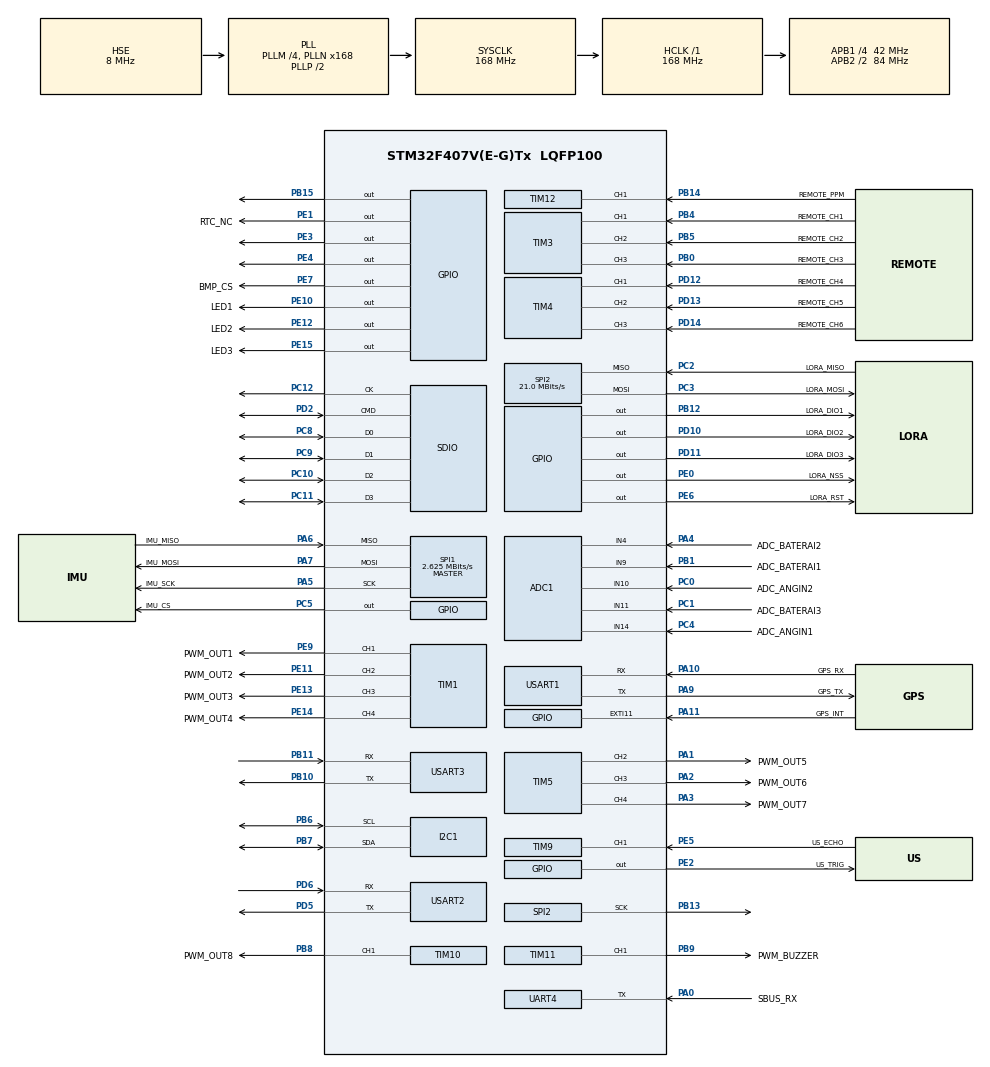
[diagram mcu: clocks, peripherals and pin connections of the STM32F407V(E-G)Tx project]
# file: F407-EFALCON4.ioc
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PD12.GPIO_Label=REMOTE_CH4
PH0-OSC_IN.Signal=RCC_OSC_IN
SH.S_TIM1_CH4.0=TIM1_CH4,PWM Generation4 CH4
TIM4.Channel-Input_Capture3_from_TI3=TIM_CHANNEL_3
SPI1.VirtualType=VM_MASTER
SPI2.VirtualType=VM_MASTER
TIM12.ICPolarity_CH2=TIM_INPUTCHANNELPOLARITY_RISING
PB10.Mode=Asynchronous
TIM12.ICPolarity_CH1=TIM_INPUTCHANNELPOLARITY_FALLING
NVIC.TIM6_DAC_IRQn=true\:5\:0\:false\:true\:true\:3\:true\:true\:true
VP_FATFS_VS_SDIO.Mode=SDIO
PC12.Signal=SDIO_CK
PB14.GPIO_Label=REMOTE_PPM
FREERTOS.Events01=IMUEvent,Dynamic,NULL;RemoteEvent,Dynamic,NULL
PE10.GPIO_PuPd=GPIO_NOPULL
PA6.GPIO_Label=IMU_MISO
PB13.Signal=SPI2_SCK
PE6.GPIO_Label=LORA_RST
RCC.SYSCLKSource=RCC_SYSCLKSOURCE_PLLCLK
FREERTOS.configENABLE_FPU=1
SPI1.Direction=SPI_DIRECTION_2LINES
UART4.Mode=MODE_RX
RCC.APB2TimFreq_Value=168000000
PB6.Signal=I2C1_SCL
VP_TIM10_VS_ClockSourceINT.Mode=Enable_Timer
PB6.Mode=I2C
SPI1.CalculateBaudRate=2.625 MBits/s
PC3.Signal=SPI2_MOSI
PE5.Signal=S_TIM9_CH1
PE1.Signal=GPIO_Output
FREERTOS.configMINIMAL_STACK_SIZE=512
TIM3.Channel-Input_Capture1_from_TI1=TIM_CHANNEL_1
TIM10.Channel=TIM_CHANNEL_1
PB12.GPIO_Label=LORA_DIO1
SH.S_TIM12_CH1.0=TIM12_CH1,Input_Capture1_from_TI1
PC4.GPIO_Label=ADC_ANGIN1
TIM1.Channel-PWM\ Generation1\ CH1=TIM_CHANNEL_1
PE9.Signal=S_TIM1_CH1
SH.S_TIM12_CH1.1=TIM12_CH1,Input_Capture2_from_TI1
PB1.GPIO_Label=ADC_BATERAI1
PC9.Mode=SD_4_bits_Wide_bus
SPI2.CalculateBaudRate=21.0 MBits/s
SH.S_TIM4_CH2.0=TIM4_CH2,Input_Capture2_from_TI2
PE2.Signal=GPIO_Output
TIM12.Channel-Input_Capture2_from_TI1=TIM_CHANNEL_2
PE10.Signal=GPIO_Output
ADC1.SamplingTime-0\#ChannelRegularConversion=ADC_SAMPLETIME_3CYCLES
Mcu.Package=LQFP100
PB9.Signal=S_TIM11_CH1
PB1.Signal=ADCx_IN9
PB14.GPIO_PuPd=GPIO_NOPULL
NVIC.TimeBase=TIM7_IRQn
SPI2.Mode=SPI_MODE_MASTER
SH.ADCx_IN14.0=ADC1_IN14,IN14
PD12.Signal=S_TIM4_CH1
NVIC.TimeBaseIP=TIM7
PA10.Signal=USART1_RX
PE12.GPIO_Label=LED2
PC11.Mode=SD_4_bits_Wide_bus
SH.ADCx_IN9.0=ADC1_IN9,IN9
RCC.APB2CLKDivider=RCC_HCLK_DIV2
SH.S_TIM4_CH1.0=TIM4_CH1,Input_Capture1_from_TI1
RCC.APB1TimFreq_Value=84000000
PB13.Mode=Full_Duplex_Master
PE10.GPIO_Label=LED1
PA4.GPIO_Label=ADC_BATERAI2
PA5.Mode=Full_Duplex_Master
FREERTOS.Tasks01=IMU_Task,48,512,Start_IMU_Task,Default,NULL,Dynamic,NULL,NULL;Remote_Task,27,512,Start_Remote_Task,Default,NULL,Dynamic,NULL,NULL;PrintSerial_Tas,24,512,Start_PrintSerial_Task,Default,NULL,Dynamic,NULL,NULL;BMP_Task,8,512,Start_BMP_Task,Default,NULL,Dynamic,NULL,NULL
ADC1.Rank-0\#ChannelRegularConversion=1
TIM3.Channel-Input_Capture2_from_TI2=TIM_CHANNEL_2
PA9.GPIO_Label=GPS_TX
PC2.Signal=SPI2_MISO
PA11.GPIO_Label=GPS_INT
PE7.PinState=GPIO_PIN_SET
TIM5.Channel-PWM\ Generation3\ CH3=TIM_CHANNEL_3
PC0.Signal=ADCx_IN10
RCC.APB1CLKDivider=RCC_HCLK_DIV4
UART4.VirtualMode=Asynchronous
PD6.Mode=Asynchronous
PA0-WKUP.GPIO_Label=SBUS_RX
PA0-WKUP.Signal=UART4_TX
PA0-WKUP.Mode=Half_duplex(single_wire_mode)
PD10.Signal=GPIO_Output
PB8.GPIO_Label=PWM_OUT8
PB11.Mode=Asynchronous
PA9.Signal=USART1_TX
TIM1.Channel-PWM\ Generation2\ CH2=TIM_CHANNEL_2
SDIO.ClockDiv=4
PE9.GPIO_Label=PWM_OUT1
PB10.Signal=USART3_TX
ARM.CMSIS.5.6.0.CMSISJjCORE=true
TIM12.Prescaler=84 - 1
PB14.Signal=S_TIM12_CH1
PA5.Signal=SPI1_SCK
PC12.Mode=SD_4_bits_Wide_bus
PE1.GPIO_Label=RTC_NC
PE14.Signal=S_TIM1_CH4
PE15.Signal=GPIO_Output
PB4.GPIO_Label=REMOTE_CH1
SPI1.Mode=SPI_MODE_MASTER
SH.S_TIM9_CH1.1=TIM9_CH1,Input_Capture2_from_TI1
PA1.GPIO_Label=PWM_OUT5
SH.S_TIM9_CH1.0=TIM9_CH1,Input_Capture1_from_TI1
SH.ADCx_IN4.0=ADC1_IN4,IN4
PA13.Mode=Serial_Wire
PC8.Mode=SD_4_bits_Wide_bus
TIM5.Channel-PWM\ Generation2\ CH2=TIM_CHANNEL_2
PA4.Signal=ADCx_IN4
TIM12.Channel-Input_Capture1_from_TI1=TIM_CHANNEL_1
PB5.Signal=S_TIM3_CH2
ADC1.master=1
PE13.GPIO_Label=PWM_OUT3
PA5.GPIO_Label=IMU_SCK
PD11.Signal=GPIO_Output
PE5.GPIO_Label=US_ECHO
USART1.VirtualMode=VM_ASYNC
PA11.Signal=GPXTI11
ProjectManager.HeapSize=0x200
NVIC.PriorityGroup=NVIC_PRIORITYGROUP_4
PE3.Signal=GPIO_Output
PC3.GPIO_Label=LORA_MOSI
TIM9.Channel-Input_Capture2_from_TI1=TIM_CHANNEL_2
TIM1.Channel-PWM\ Generation3\ CH3=TIM_CHANNEL_3
PD2.Signal=SDIO_CMD
PB0.Signal=S_TIM3_CH3
PC1.Signal=ADCx_IN11
Mcu.Family=STM32F4
PC3.Mode=Full_Duplex_Master
PA6.Mode=Full_Duplex_Master
RCC.CortexFreq_Value=168000000
PE11.GPIO_Label=PWM_OUT2
PC10.Signal=SDIO_D2
SH.S_TIM5_CH2.0=TIM5_CH2,PWM Generation2 CH2
PC0.GPIO_Label=ADC_ANGIN2
PB0.GPIO_Label=REMOTE_CH3
PB11.Signal=USART3_RX
PB15.Signal=GPIO_Output
ProjectManager.StackSize=0x400
VP_FREERTOS_VS_CMSIS_V2.Mode=CMSIS_V2
TIM4.Channel-Input_Capture1_from_TI1=TIM_CHANNEL_1
PD13.Signal=S_TIM4_CH2
TIM3.Channel-Input_Capture3_from_TI3=TIM_CHANNEL_3
TIM1.Channel-PWM\ Generation4\ CH4=TIM_CHANNEL_4
PD11.GPIO_Label=LORA_DIO3
RCC.HCLKFreq_Value=168000000
SH.S_TIM5_CH3.0=TIM5_CH3,PWM Generation3 CH3
RCC.AHBFreq_Value=168000000
PH0-OSC_IN.Mode=HSE-External-Oscillator
PD5.Mode=Asynchronous
ADC1.Channel-0\#ChannelRegularConversion=ADC_CHANNEL_9
RCC.HSE_VALUE=8000000
PE13.Signal=S_TIM1_CH3
TIM5.Channel-PWM\ Generation4\ CH4=TIM_CHANNEL_4
PA14.Mode=Serial_Wire
PA10.GPIO_Label=GPS_RX
PB7.Signal=I2C1_SDA
SH.S_TIM3_CH1.0=TIM3_CH1,Input_Capture1_from_TI1
TIM6.Period=100 - 1
PE4.Signal=GPIO_Output
PH1-OSC_OUT.Mode=HSE-External-Oscillator
PD13.GPIO_Label=REMOTE_CH5
PA6.Signal=SPI1_MISO
USART2.VirtualMode=VM_ASYNC
SH.S_TIM10_CH1.0=TIM10_CH1,PWM Generation1 CH1
PA2.GPIO_Label=PWM_OUT6
PE0.GPIO_Label=LORA_NSS
PB5.GPIO_Label=REMOTE_CH2
SPI2.Direction=SPI_DIRECTION_2LINES
PC5.Signal=GPIO_Output
PE7.Signal=GPIO_Output
PD6.Signal=USART2_RX
SH.S_TIM11_CH1.0=TIM11_CH1,PWM Generation1 CH1
SPI1.BaudRatePrescaler=SPI_BAUDRATEPRESCALER_32
PE2.GPIO_Label=US_TRIG
PC2.GPIO_Label=LORA_MISO
NVIC.TIM7_IRQn=true\:0\:0\:false\:false\:true\:false\:false\:true
PB4.Signal=S_TIM3_CH1
PA3.Signal=S_TIM5_CH4
PE10.PinState=GPIO_PIN_SET
RCC.PLLSourceVirtual=RCC_PLLSOURCE_HSE
PA7.Mode=Full_Duplex_Master
PB9.GPIO_Label=PWM_BUZZER
PA10.Mode=Asynchronous
PC11.Signal=SDIO_D3
VP_SYS_VS_tim7.Mode=TIM7
PC8.Signal=SDIO_D0
TIM6.Prescaler=84 - 1
PC4.Signal=ADCx_IN14
PC10.Mode=SD_4_bits_Wide_bus
VP_TIM6_VS_ClockSourceINT.Mode=Enable_Timer
ARM.CMSIS.5.6.0.CMSISJjDSP=Library
PC2.Mode=Full_Duplex_Master
PE14.GPIO_Label=PWM_OUT4
PD5.Signal=USART2_TX
PC5.GPIO_PuPd=GPIO_NOPULL
SH.S_TIM3_CH3.0=TIM3_CH3,Input_Capture3_from_TI3
NVIC.USART2_IRQn=true\:5\:0\:false\:false\:true\:true\:true\:true
TIM4.Channel-Input_Capture2_from_TI2=TIM_CHANNEL_2
VP_TIM11_VS_ClockSourceINT.Mode=Enable_Timer
PA13.Signal=SYS_JTMS-SWDIO
PA9.Mode=Asynchronous
SH.S_TIM1_CH1.0=TIM1_CH1,PWM Generation1 CH1
PE15.GPIO_Label=LED3
ProjectManager.TargetToolchain=STM32CubeIDE
NVIC.TIM8_BRK_TIM12_IRQn=true\:5\:0\:false\:true\:true\:2\:true\:true\:true
SH.S_TIM4_CH3.0=TIM4_CH3,Input_Capture3_from_TI3
PD10.GPIO_Label=LORA_DIO2
PE11.Signal=S_TIM1_CH2
RCC.LSE_VALUE=32768
PA1.Signal=S_TIM5_CH2
TIM9.Channel-Input_Capture1_from_TI1=TIM_CHANNEL_1
PD2.Mode=SD_4_bits_Wide_bus
SH.S_TIM3_CH2.0=TIM3_CH2,Input_Capture2_from_TI2
board=custom
RCC.VCOOutputFreq_Value=336000000
VP_ARM.CMSIS_VS_CMSISJjDSP_1.7.0_5.6.0.Mode=CMSISJjDSP
RCC.APB2Freq_Value=84000000
SH.ADCx_IN11.0=ADC1_IN11,IN11
SH.S_TIM1_CH2.0=TIM1_CH2,PWM Generation2 CH2
VP_TIM2_VS_ClockSourceINT.Mode=Internal
PC1.GPIO_Label=ADC_BATERAI3
PH1-OSC_OUT.Signal=RCC_OSC_OUT
SH.S_TIM5_CH4.0=TIM5_CH4,PWM Generation4 CH4
PD14.GPIO_Label=REMOTE_CH6
PE6.Signal=GPIO_Output
Mcu.Name=STM32F407V(E-G)Tx
PE0.Signal=GPIO_Output
PE7.GPIO_Label=BMP_CS
PE12.Signal=GPIO_Output
PA2.Signal=S_TIM5_CH3
PE12.PinState=GPIO_PIN_SET
PD14.Signal=S_TIM4_CH3
RCC.48MHZClocksFreq_Value=48000000
RCC.SYSCLKFreq_VALUE=168000000
PA7.GPIO_Label=IMU_MOSI
PC5.PinState=GPIO_PIN_SET
PC5.GPIO_Label=IMU_CS
USART3.VirtualMode=VM_ASYNC
PB7.Mode=I2C
PA14.Signal=SYS_JTCK-SWCLK
SH.ADCx_IN10.0=ADC1_IN10,IN10
SH.S_TIM1_CH3.0=TIM1_CH3,PWM Generation3 CH3
RCC.HSI_VALUE=16000000
RCC.PLLQ=7
ADC1.NbrOfConversionFlag=1
RCC.PLLM=4
RCC.PLLN=168
TIM11.Channel=TIM_CHANNEL_1
PB8.Signal=S_TIM10_CH1
PC9.Signal=SDIO_D1
RCC.APB1Freq_Value=42000000
PB12.Signal=GPIO_Output
PA3.GPIO_Label=PWM_OUT7
PA7.Signal=SPI1_MOSI

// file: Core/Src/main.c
/* USER CODE BEGIN Header */
/**
  ******************************************************************************
  * @file           : main.c
  * @brief          : Main program body
  ******************************************************************************
  * @attention
  *
  * <h2><center>&copy; Copyright (c) 2021 STMicroelectronics.
  * All rights reserved.</center></h2>
  *
  * This software component is licensed by ST under BSD 3-Clause license,
  * the "License"; You may not use this file except in compliance with the
  * License. You may obtain a copy of the License at:
  *                        opensource.org/licenses/BSD-3-Clause
  *
  ******************************************************************************
  */
/* USER CODE END Header */
#include "main.h"
#include "cmsis_os.h"
#include "fatfs.h"

/* USER CODE BEGIN Includes */
#include <stdio.h>
#include <string.h>
#include <stdbool.h>

#include "MPU9250.h"
#include "IMU.h"
#include "Fusion.h"
#include "bmp2.h"
#include "retarget.h"
#include "bmp2_app.h"
#include "Kalman.h"
/* USER CODE END Includes */

/* USER CODE BEGIN PD */
#define SERIAL_DEBUG huart2
/* USER CODE END PD */

ADC_HandleTypeDef hadc1;

I2C_HandleTypeDef hi2c1;

SD_HandleTypeDef hsd;

SPI_HandleTypeDef hspi1;
SPI_HandleTypeDef hspi2;

TIM_HandleTypeDef htim1;
TIM_HandleTypeDef htim2;
TIM_HandleTypeDef htim3;
TIM_HandleTypeDef htim4;
TIM_HandleTypeDef htim5;
TIM_HandleTypeDef htim6;
TIM_HandleTypeDef htim9;
TIM_HandleTypeDef htim10;
TIM_HandleTypeDef htim11;
TIM_HandleTypeDef htim12;

UART_HandleTypeDef huart4;
UART_HandleTypeDef huart1;
UART_HandleTypeDef huart2;
UART_HandleTypeDef huart3;

/* Definitions for IMU_Task */
osThreadId_t IMU_TaskHandle;
const osThreadAttr_t IMU_Task_attributes = {
  .name = "IMU_Task",
  .stack_size = 512 * 4,
  .priority = (osPriority_t) osPriorityRealtime,
};
/* Definitions for Remote_Task */
osThreadId_t Remote_TaskHandle;
const osThreadAttr_t Remote_Task_attributes = {
  .name = "Remote_Task",
  .stack_size = 512 * 4,
  .priority = (osPriority_t) osPriorityNormal3,
};
/* Definitions for PrintSerial_Tas */
osThreadId_t PrintSerial_TasHandle;
const osThreadAttr_t PrintSerial_Tas_attributes = {
  .name = "PrintSerial_Tas",
  .stack_size = 512 * 4,
  .priority = (osPriority_t) osPriorityNormal,
};
/* Definitions for BMP_Task */
osThreadId_t BMP_TaskHandle;
const osThreadAttr_t BMP_Task_attributes = {
  .name = "BMP_Task",
  .stack_size = 512 * 4,
  .priority = (osPriority_t) osPriorityLow,
};
/* Definitions for IMUEvent */
osEventFlagsId_t IMUEventHandle;
const osEventFlagsAttr_t IMUEvent_attributes = {
  .name = "IMUEvent"
};
/* Definitions for RemoteEvent */
osEventFlagsId_t RemoteEventHandle;
const osEventFlagsAttr_t RemoteEvent_attributes = {
  .name = "RemoteEvent"
};
/* USER CODE BEGIN PV */
//String
uint8_t strBuffer[512];
uint16_t strSize = 0;

//IMU
float MPU9250_selfTest[6];
MPU9250_t mpu9250;
float accX, accY, accZ;
float magX, magY, magZ;
float gyrX, gyrY, gyrZ;
float IMURateFreq = 0;
float quaternion[4];
float delta;
bool updateIMU = false;
bool updateRemote = true;
FusionAhrs fusionahrs;
static uint32_t cntNow;
static uint32_t cntPrev;
FusionVector3 accel;
FusionVector3 gyro;
FusionVector3 magnet;
FusionEulerAngles eulerAngles;
FusionEulerAngles eulerAnglesRef;

//Remote
RC_t PPMRC;
FusionEulerAngles eulerInput;
FusionEulerAngles error;
volatile uint32_t PPMOutput[9];

//Position Controller
volatile Velocity_t inputVel;

/* USER CODE END PV */

void SystemClock_Config(void);
static void MX_GPIO_Init(void);
static void MX_I2C1_Init(void);
static void MX_SDIO_SD_Init(void);
static void MX_SPI1_Init(void);
static void MX_SPI2_Init(void);
static void MX_TIM5_Init(void);
static void MX_TIM9_Init(void);
static void MX_TIM10_Init(void);
static void MX_TIM11_Init(void);
static void MX_UART4_Init(void);
static void MX_USART1_UART_Init(void);
static void MX_USART2_UART_Init(void);
static void MX_USART3_UART_Init(void);
static void MX_ADC1_Init(void);
static void MX_TIM2_Init(void);
static void MX_TIM6_Init(void);
static void MX_TIM12_Init(void);
static void MX_TIM1_Init(void);
static void MX_TIM3_Init(void);
static void MX_TIM4_Init(void);
void Start_IMU_Task(void *argument);
void Start_Remote_Task(void *argument);
void Start_PrintSerial_Task(void *argument);
void Start_BMP_Task(void *argument);

static void MX_NVIC_Init(void);

/* USER CODE BEGIN 0 */
uint32_t DWT_Init(void)
{
    /* Disable TRC */
    CoreDebug->DEMCR &= ~CoreDebug_DEMCR_TRCENA_Msk; // ~0x01000000;
    /* Enable TRC */
    CoreDebug->DEMCR |=  CoreDebug_DEMCR_TRCENA_Msk; // 0x01000000;
    /* Disable clock cycle counter */
    DWT->CTRL &= ~DWT_CTRL_CYCCNTENA_Msk; //~0x00000001;
    /* Enable  clock cycle counter */
    DWT->CTRL |=  DWT_CTRL_CYCCNTENA_Msk; //0x00000001;
    /* Reset the clock cycle counter value */
    DWT->CYCCNT = 0;
    /* 3 NO OPERATION instructions */
    __ASM volatile ("NOP");
    __ASM volatile ("NOP");
    __ASM volatile ("NOP");
    /* Check if clock cycle counter has started */
    if(DWT->CYCCNT)
    {
       return 0; /*clock cycle counter started*/
    }
    else
    {
      return 1; /*clock cycle counter not started*/
    }
}

uint32_t DWT_GetuS(){
	return  DWT->CYCCNT / (SystemCoreClock / 1000000U);
}

static int8_t get_data(uint32_t period, struct bmp2_config *conf, struct bmp2_dev *dev){
    int8_t rslt = BMP2_E_NULL_PTR;
    int8_t idx = 1;
    struct bmp2_status status;
    struct bmp2_data comp_data;

    printf("Measurement delay : %lu us\r\n", (long unsigned int)period);

    while (idx <= 50)
    {
        rslt = bmp2_get_status(&status, dev);
        bmp2_error_codes_print_result("bmp2_get_status", rslt);

        if (status.measuring == BMP2_MEAS_DONE)
        {
            /* Delay between measurements */
            dev->delay_us(period, dev->intf_ptr);

            /* Read compensated data */
            rslt = bmp2_get_sensor_data(&comp_data, dev);
            bmp2_error_codes_print_result("bmp2_get_sensor_data", rslt);

            #ifdef BMP2_64BIT_COMPENSATION
            comp_data.pressure = comp_data.pressure / 256;
            #endif

            #ifdef BMP2_DOUBLE_COMPENSATION
            printf("Data[%d]:    Temperature: %f deg C	Pressure: %f Pa\r\n",
                   idx,
                   comp_data.temperature,
                   comp_data.pressure);
            #else
            printf("Data[%d]:    Temperature: %ld deg C	Pressure: %lu Pa\n", idx, (long int)comp_data.temperature,
                   (long unsigned int)comp_data.pressure);
            #endif

            idx++;
        }
    }

    return rslt;
}

void bmp280_setup(struct bmp2_config *conf, struct bmp2_dev *dev){

}
/* USER CODE END 0 */

int main(void)
{

  /* MCU Configuration--------------------------------------------------------*/

  /* Reset of all peripherals, Initializes the Flash interface and the Systick. */
  HAL_Init();

  /* Configure the system clock */
  SystemClock_Config();

  /* Initialize all configured peripherals */
  MX_GPIO_Init();
  MX_I2C1_Init();
  MX_SDIO_SD_Init();
  MX_SPI1_Init();
  MX_SPI2_Init();
  MX_TIM5_Init();
  MX_TIM9_Init();
  MX_TIM10_Init();
  MX_TIM11_Init();
  MX_UART4_Init();
  MX_USART1_UART_Init();
  MX_USART2_UART_Init();
  MX_USART3_UART_Init();
  MX_ADC1_Init();
  MX_TIM2_Init();
  MX_TIM6_Init();
  MX_TIM12_Init();
  MX_FATFS_Init();
  MX_TIM1_Init();
  MX_TIM3_Init();
  MX_TIM4_Init();

  /* Initialize interrupts */
  MX_NVIC_Init();
  /* USER CODE BEGIN 2 */
  HAL_Delay(25);
  RetargetInit(&SERIAL_DEBUG);

  printf("Coba printf\r\n");

  printf("Mulai!\r\n");

  if(DWT_Init()){
 	  printf("DWT gagal inisialisasi!\r\n");
 	  while(1);
   }

  MPU9250_init(&mpu9250, &hspi1, IMU_CS_GPIO_Port, IMU_CS_Pin);
  int statusCode = MPU9250_begin(&mpu9250);
  if(statusCode < 0){
	  printf("IMU gagal inisialisasi");
	  while(1);
  }

  statusCode = MPU9250_enableDataReadyInterrupt(&mpu9250);
  if(statusCode < 0){
	  printf("Data ready Interrupt gagal! code: %d\r\n", statusCode);
	  while(1);
  }

  printf("Memulai kalibrasi accelerometer...\r\n");

  MPU9250_calibrateAccel(&mpu9250);

  printf("Kalibrasi accelerometer sukses!\r\n");

  printf("Memulai kalibrasi magnetometer...\r\n");
  HAL_Delay(2000);

  //MPU9250_calibrateMag(&mpu9250);

  printf("Kalibrasi magnetometer sukses!\r\n");
  HAL_Delay(2000);

  printf("MPU9250 Self Test\r\n");
  HAL_UART_Transmit(&SERIAL_DEBUG, strBuffer, strSize, HAL_MAX_DELAY);

  MPU9250_SelfTest(&mpu9250, MPU9250_selfTest);

  printf("x-Axis self test: acceleration trim within: %f %% of factory value\r\n", MPU9250_selfTest[0]);

  printf("y-Axis self test: acceleration trim within: %f %% of factory value\r\n", MPU9250_selfTest[1]);

  printf("z-Axis self test: acceleration trim within: %f %% of factory value\r\n", MPU9250_selfTest[2]);

  printf("x-Axis self test: gyration trim within: %f %% of factory value\r\n", MPU9250_selfTest[3]);

  printf("y-Axis self test: gyration trim within: %f %% of factory value\r\n", MPU9250_selfTest[4]);

  printf("z-Axis self test: gyration trim within: %f %% of factory value\r\n", MPU9250_selfTest[5]);
  //while(1);

  FusionAhrsInitialise(&fusionahrs, 0.5);

  HAL_Delay(3000);

  //MPU9250_begin();

  /*uint8_t imu_whoami = MPU9250_WhoAmI();

  strSize = sprintf((char*)strBuffer, "Hasil Who Am I MPU9250: %d\r\n", imu_whoami);
  HAL_UART_Transmit(&SERIAL_DEBUG, strBuffer, strSize, HAL_MAX_DELAY);

  if(imu_whoami != 0x71 && imu_whoami != 0x73){
	  strSize = sprintf((char*)strBuffer, "Gagal inisialiasasi IMU!\r\n");
	  HAL_UART_Transmit(&SERIAL_DEBUG, strBuffer, strSize, HAL_MAX_DELAY);
	  while(1);
  } else {
	  MPU9250_SelfTest(MPU9250_selfTest);

	  strSize = sprintf((char*)strBuffer, "x-Axis self test: acceleration trim within: %f %% of factory value\r\n", MPU9250_selfTest[0]);
	  HAL_UART_Transmit(&SERIAL_DEBUG, strBuffer, strSize, HAL_MAX_DELAY);

	  strSize = sprintf((char*)strBuffer, "y-Axis self test: acceleration trim within: %f %% of factory value\r\n", MPU9250_selfTest[1]);
	  HAL_UART_Transmit(&SERIAL_DEBUG, strBuffer, strSize, HAL_MAX_DELAY);

	  strSize = sprintf((char*)strBuffer, "z-Axis self test: acceleration trim within: %f %% of factory value\r\n", MPU9250_selfTest[2]);
	  HAL_UART_Transmit(&SERIAL_DEBUG, strBuffer, strSize, HAL_MAX_DELAY);

	  strSize = sprintf((char*)strBuffer, "x-Axis self test: gyration trim within: %f %% of factory value\r\n", MPU9250_selfTest[3]);
	  HAL_UART_Transmit(&SERIAL_DEBUG, strBuffer, strSize, HAL_MAX_DELAY);

	  strSize = sprintf((char*)strBuffer, "y-Axis self test: gyration trim within: %f %% of factory value\r\n", MPU9250_selfTest[4]);
	  HAL_UART_Transmit(&SERIAL_DEBUG, strBuffer, strSize, HAL_MAX_DELAY);

	  strSize = sprintf((char*)strBuffer, "z-Axis self test: gyration trim within: %f %% of factory value\r\n", MPU9250_selfTest[5]);
	  HAL_UART_Transmit(&SERIAL_DEBUG, strBuffer, strSize, HAL_MAX_DELAY);
  }

  uint8_t magnet_whoami = MPU9250_AK8963WhoAmI();

  strSize = sprintf((char*)strBuffer, "Hasil Who Am I AK8963: %d\r\n", magnet_whoami);
  HAL_UART_Transmit(&SERIAL_DEBUG, strBuffer, strSize, HAL_MAX_DELAY);

  if(magnet_whoami != 0x48){
	  strSize = sprintf((char*)strBuffer, "Gagal inisialiasasi Magnetometer!\r\n");
	  HAL_UART_Transmit(&SERIAL_DEBUG, strBuffer, strSize, HAL_MAX_DELAY);
	  while(1);
  }*/
  /* USER CODE END 2 */

  /* Init scheduler */
  osKernelInitialize();

  /* Create the thread(s) */
  /* creation of IMU_Task */
  IMU_TaskHandle = osThreadNew(Start_IMU_Task, NULL, &IMU_Task_attributes);

  /* creation of Remote_Task */
  Remote_TaskHandle = osThreadNew(Start_Remote_Task, NULL, &Remote_Task_attributes);

  /* creation of PrintSerial_Tas */
  PrintSerial_TasHandle = osThreadNew(Start_PrintSerial_Task, NULL, &PrintSerial_Tas_attributes);

  /* creation of BMP_Task */
  BMP_TaskHandle = osThreadNew(Start_BMP_Task, NULL, &BMP_Task_attributes);

  /* Create the event(s) */
  /* creation of IMUEvent */
  IMUEventHandle = osEventFlagsNew(&IMUEvent_attributes);

  /* creation of RemoteEvent */
  RemoteEventHandle = osEventFlagsNew(&RemoteEvent_attributes);

  /* Start scheduler */
  osKernelStart();

  /* We should never get here as control is now taken by the scheduler */
  /* Infinite loop */
  while (1)
  {

  }
}

void SystemClock_Config(void)
{
  RCC_OscInitTypeDef RCC_OscInitStruct = {0};
  RCC_ClkInitTypeDef RCC_ClkInitStruct = {0};

  /** Configure the main internal regulator output voltage
  */
  __HAL_RCC_PWR_CLK_ENABLE();
  __HAL_PWR_VOLTAGESCALING_CONFIG(PWR_REGULATOR_VOLTAGE_SCALE1);
  /** Initializes the RCC Oscillators according to the specified parameters
  * in the RCC_OscInitTypeDef structure.
  */
  RCC_OscInitStruct.OscillatorType = RCC_OSCILLATORTYPE_HSE;
  RCC_OscInitStruct.HSEState = RCC_HSE_ON;
  RCC_OscInitStruct.PLL.PLLState = RCC_PLL_ON;
  RCC_OscInitStruct.PLL.PLLSource = RCC_PLLSOURCE_HSE;
  RCC_OscInitStruct.PLL.PLLM = 4;
  RCC_OscInitStruct.PLL.PLLN = 168;
  RCC_OscInitStruct.PLL.PLLP = RCC_PLLP_DIV2;
  RCC_OscInitStruct.PLL.PLLQ = 7;
  if (HAL_RCC_OscConfig(&RCC_OscInitStruct) != HAL_OK)
  {
    Error_Handler();
  }
  /** Initializes the CPU, AHB and APB buses clocks
  */
  RCC_ClkInitStruct.ClockType = RCC_CLOCKTYPE_HCLK|RCC_CLOCKTYPE_SYSCLK
                              |RCC_CLOCKTYPE_PCLK1|RCC_CLOCKTYPE_PCLK2;
  RCC_ClkInitStruct.SYSCLKSource = RCC_SYSCLKSOURCE_PLLCLK;
  RCC_ClkInitStruct.AHBCLKDivider = RCC_SYSCLK_DIV1;
  RCC_ClkInitStruct.APB1CLKDivider = RCC_HCLK_DIV4;
  RCC_ClkInitStruct.APB2CLKDivider = RCC_HCLK_DIV2;

  if (HAL_RCC_ClockConfig(&RCC_ClkInitStruct, FLASH_LATENCY_5) != HAL_OK)
  {
    Error_Handler();
  }
}

/**
  * @brief NVIC Configuration.
  * @retval None
  */
static void MX_NVIC_Init(void)
{
  /* TIM8_BRK_TIM12_IRQn interrupt configuration */
  HAL_NVIC_SetPriority(TIM8_BRK_TIM12_IRQn, 5, 0);
  HAL_NVIC_EnableIRQ(TIM8_BRK_TIM12_IRQn);
  /* TIM6_DAC_IRQn interrupt configuration */
  HAL_NVIC_SetPriority(TIM6_DAC_IRQn, 5, 0);
  HAL_NVIC_EnableIRQ(TIM6_DAC_IRQn);
}

static void MX_ADC1_Init(void)
{

  ADC_ChannelConfTypeDef sConfig = {0};

  /** Configure the global features of the ADC (Clock, Resolution, Data Alignment and number of conversion)
  */
  hadc1.Instance = ADC1;
  hadc1.Init.ClockPrescaler = ADC_CLOCK_SYNC_PCLK_DIV4;
  hadc1.Init.Resolution = ADC_RESOLUTION_12B;
  hadc1.Init.ScanConvMode = DISABLE;
  hadc1.Init.ContinuousConvMode = DISABLE;
  hadc1.Init.DiscontinuousConvMode = DISABLE;
  hadc1.Init.ExternalTrigConvEdge = ADC_EXTERNALTRIGCONVEDGE_NONE;
  hadc1.Init.ExternalTrigConv = ADC_SOFTWARE_START;
  hadc1.Init.DataAlign = ADC_DATAALIGN_RIGHT;
  hadc1.Init.NbrOfConversion = 1;
  hadc1.Init.DMAContinuousRequests = DISABLE;
  hadc1.Init.EOCSelection = ADC_EOC_SINGLE_CONV;
  if (HAL_ADC_Init(&hadc1) != HAL_OK)
  {
    Error_Handler();
  }
  /** Configure for the selected ADC regular channel its corresponding rank in the sequencer and its sample time.
  */
  sConfig.Channel = ADC_CHANNEL_9;
  sConfig.Rank = 1;
  sConfig.SamplingTime = ADC_SAMPLETIME_3CYCLES;
  if (HAL_ADC_ConfigChannel(&hadc1, &sConfig) != HAL_OK)
  {
    Error_Handler();
  }

}

static void MX_I2C1_Init(void)
{

  hi2c1.Instance = I2C1;
  hi2c1.Init.ClockSpeed = 100000;
  hi2c1.Init.DutyCycle = I2C_DUTYCYCLE_2;
  hi2c1.Init.OwnAddress1 = 0;
  hi2c1.Init.AddressingMode = I2C_ADDRESSINGMODE_7BIT;
  hi2c1.Init.DualAddressMode = I2C_DUALADDRESS_DISABLE;
  hi2c1.Init.OwnAddress2 = 0;
  hi2c1.Init.GeneralCallMode = I2C_GENERALCALL_DISABLE;
  hi2c1.Init.NoStretchMode = I2C_NOSTRETCH_DISABLE;
  if (HAL_I2C_Init(&hi2c1) != HAL_OK)
  {
    Error_Handler();
  }

}

static void MX_SDIO_SD_Init(void)
{

  hsd.Instance = SDIO;
  hsd.Init.ClockEdge = SDIO_CLOCK_EDGE_RISING;
  hsd.Init.ClockBypass = SDIO_CLOCK_BYPASS_DISABLE;
  hsd.Init.ClockPowerSave = SDIO_CLOCK_POWER_SAVE_DISABLE;
  hsd.Init.BusWide = SDIO_BUS_WIDE_1B;
  hsd.Init.HardwareFlowControl = SDIO_HARDWARE_FLOW_CONTROL_DISABLE;
  hsd.Init.ClockDiv = 4;

}

static void MX_SPI1_Init(void)
{

  /* SPI1 parameter configuration*/
  hspi1.Instance = SPI1;
  hspi1.Init.Mode = SPI_MODE_MASTER;
  hspi1.Init.Direction = SPI_DIRECTION_2LINES;
  hspi1.Init.DataSize = SPI_DATASIZE_8BIT;
  hspi1.Init.CLKPolarity = SPI_POLARITY_LOW;
  hspi1.Init.CLKPhase = SPI_PHASE_1EDGE;
  hspi1.Init.NSS = SPI_NSS_SOFT;
  hspi1.Init.BaudRatePrescaler = SPI_BAUDRATEPRESCALER_32;
  hspi1.Init.FirstBit = SPI_FIRSTBIT_MSB;
  hspi1.Init.TIMode = SPI_TIMODE_DISABLE;
  hspi1.Init.CRCCalculation = SPI_CRCCALCULATION_DISABLE;
  hspi1.Init.CRCPolynomial = 10;
  if (HAL_SPI_Init(&hspi1) != HAL_OK)
  {
    Error_Handler();
  }

}

static void MX_SPI2_Init(void)
{

  /* SPI2 parameter configuration*/
  hspi2.Instance = SPI2;
  hspi2.Init.Mode = SPI_MODE_MASTER;
  hspi2.Init.Direction = SPI_DIRECTION_2LINES;
  hspi2.Init.DataSize = SPI_DATASIZE_8BIT;
  hspi2.Init.CLKPolarity = SPI_POLARITY_LOW;
  hspi2.Init.CLKPhase = SPI_PHASE_1EDGE;
  hspi2.Init.NSS = SPI_NSS_SOFT;
  hspi2.Init.BaudRatePrescaler = SPI_BAUDRATEPRESCALER_2;
  hspi2.Init.FirstBit = SPI_FIRSTBIT_MSB;
  hspi2.Init.TIMode = SPI_TIMODE_DISABLE;
  hspi2.Init.CRCCalculation = SPI_CRCCALCULATION_DISABLE;
  hspi2.Init.CRCPolynomial = 10;
  if (HAL_SPI_Init(&hspi2) != HAL_OK)
  {
    Error_Handler();
  }

}

static void MX_TIM1_Init(void)
{

  TIM_MasterConfigTypeDef sMasterConfig = {0};
  TIM_OC_InitTypeDef sConfigOC = {0};
  TIM_BreakDeadTimeConfigTypeDef sBreakDeadTimeConfig = {0};

  htim1.Instance = TIM1;
  htim1.Init.Prescaler = 0;
  htim1.Init.CounterMode = TIM_COUNTERMODE_UP;
  htim1.Init.Period = 65535;
  htim1.Init.ClockDivision = TIM_CLOCKDIVISION_DIV1;
  htim1.Init.RepetitionCounter = 0;
  htim1.Init.AutoReloadPreload = TIM_AUTORELOAD_PRELOAD_DISABLE;
  if (HAL_TIM_PWM_Init(&htim1) != HAL_OK)
  {
    Error_Handler();
  }
  sMasterConfig.MasterOutputTrigger = TIM_TRGO_RESET;
  sMasterConfig.MasterSlaveMode = TIM_MASTERSLAVEMODE_DISABLE;
  if (HAL_TIMEx_MasterConfigSynchronization(&htim1, &sMasterConfig) != HAL_OK)
  {
    Error_Handler();
  }
  sConfigOC.OCMode = TIM_OCMODE_PWM1;
  sConfigOC.Pulse = 0;
  sConfigOC.OCPolarity = TIM_OCPOLARITY_HIGH;
  sConfigOC.OCNPolarity = TIM_OCNPOLARITY_HIGH;
  sConfigOC.OCFastMode = TIM_OCFAST_DISABLE;
  sConfigOC.OCIdleState = TIM_OCIDLESTATE_RESET;
  sConfigOC.OCNIdleState = TIM_OCNIDLESTATE_RESET;
  if (HAL_TIM_PWM_ConfigChannel(&htim1, &sConfigOC, TIM_CHANNEL_1) != HAL_OK)
  {
    Error_Handler();
  }
  if (HAL_TIM_PWM_ConfigChannel(&htim1, &sConfigOC, TIM_CHANNEL_2) != HAL_OK)
  {
    Error_Handler();
  }
  if (HAL_TIM_PWM_ConfigChannel(&htim1, &sConfigOC, TIM_CHANNEL_3) != HAL_OK)
  {
    Error_Handler();
  }
  if (HAL_TIM_PWM_ConfigChannel(&htim1, &sConfigOC, TIM_CHANNEL_4) != HAL_OK)
  {
    Error_Handler();
  }
  sBreakDeadTimeConfig.OffStateRunMode = TIM_OSSR_DISABLE;
  sBreakDeadTimeConfig.OffStateIDLEMode = TIM_OSSI_DISABLE;
  sBreakDeadTimeConfig.LockLevel = TIM_LOCKLEVEL_OFF;
  sBreakDeadTimeConfig.DeadTime = 0;
  sBreakDeadTimeConfig.BreakState = TIM_BREAK_DISABLE;
  sBreakDeadTimeConfig.BreakPolarity = TIM_BREAKPOLARITY_HIGH;
  sBreakDeadTimeConfig.AutomaticOutput = TIM_AUTOMATICOUTPUT_DISABLE;
  if (HAL_TIMEx_ConfigBreakDeadTime(&htim1, &sBreakDeadTimeConfig) != HAL_OK)
  {
    Error_Handler();
  }
  HAL_TIM_MspPostInit(&htim1);

}

static void MX_TIM2_Init(void)
{

  TIM_ClockConfigTypeDef sClockSourceConfig = {0};
  TIM_MasterConfigTypeDef sMasterConfig = {0};

  htim2.Instance = TIM2;
  htim2.Init.Prescaler = 0;
  htim2.Init.CounterMode = TIM_COUNTERMODE_UP;
  htim2.Init.Period = 4294967295;
  htim2.Init.ClockDivision = TIM_CLOCKDIVISION_DIV1;
  htim2.Init.AutoReloadPreload = TIM_AUTORELOAD_PRELOAD_DISABLE;
  if (HAL_TIM_Base_Init(&htim2) != HAL_OK)
  {
    Error_Handler();
  }
  sClockSourceConfig.ClockSource = TIM_CLOCKSOURCE_INTERNAL;
  if (HAL_TIM_ConfigClockSource(&htim2, &sClockSourceConfig) != HAL_OK)
  {
    Error_Handler();
  }
  sMasterConfig.MasterOutputTrigger = TIM_TRGO_RESET;
  sMasterConfig.MasterSlaveMode = TIM_MASTERSLAVEMODE_DISABLE;
  if (HAL_TIMEx_MasterConfigSynchronization(&htim2, &sMasterConfig) != HAL_OK)
  {
    Error_Handler();
  }

}

static void MX_TIM3_Init(void)
{

  TIM_MasterConfigTypeDef sMasterConfig = {0};
  TIM_IC_InitTypeDef sConfigIC = {0};

  htim3.Instance = TIM3;
  htim3.Init.Prescaler = 0;
  htim3.Init.CounterMode = TIM_COUNTERMODE_UP;
  htim3.Init.Period = 65535;
  htim3.Init.ClockDivision = TIM_CLOCKDIVISION_DIV1;
  htim3.Init.AutoReloadPreload = TIM_AUTORELOAD_PRELOAD_DISABLE;
  if (HAL_TIM_IC_Init(&htim3) != HAL_OK)
  {
    Error_Handler();
  }
  sMasterConfig.MasterOutputTrigger = TIM_TRGO_RESET;
  sMasterConfig.MasterSlaveMode = TIM_MASTERSLAVEMODE_DISABLE;
  if (HAL_TIMEx_MasterConfigSynchronization(&htim3, &sMasterConfig) != HAL_OK)
  {
    Error_Handler();
  }
  sConfigIC.ICPolarity = TIM_INPUTCHANNELPOLARITY_RISING;
  sConfigIC.ICSelection = TIM_ICSELECTION_DIRECTTI;
  sConfigIC.ICPrescaler = TIM_ICPSC_DIV1;
  sConfigIC.ICFilter = 0;
  if (HAL_TIM_IC_ConfigChannel(&htim3, &sConfigIC, TIM_CHANNEL_1) != HAL_OK)
  {
    Error_Handler();
  }
  if (HAL_TIM_IC_ConfigChannel(&htim3, &sConfigIC, TIM_CHANNEL_2) != HAL_OK)
  {
    Error_Handler();
  }
  if (HAL_TIM_IC_ConfigChannel(&htim3, &sConfigIC, TIM_CHANNEL_3) != HAL_OK)
  {
    Error_Handler();
  }

}

static void MX_TIM4_Init(void)
{

  TIM_MasterConfigTypeDef sMasterConfig = {0};
  TIM_IC_InitTypeDef sConfigIC = {0};

  htim4.Instance = TIM4;
  htim4.Init.Prescaler = 0;
  htim4.Init.CounterMode = TIM_COUNTERMODE_UP;
  htim4.Init.Period = 65535;
  htim4.Init.ClockDivision = TIM_CLOCKDIVISION_DIV1;
  htim4.Init.AutoReloadPreload = TIM_AUTORELOAD_PRELOAD_DISABLE;
  if (HAL_TIM_IC_Init(&htim4) != HAL_OK)
  {
    Error_Handler();
  }
  sMasterConfig.MasterOutputTrigger = TIM_TRGO_RESET;
  sMasterConfig.MasterSlaveMode = TIM_MASTERSLAVEMODE_DISABLE;
  if (HAL_TIMEx_MasterConfigSynchronization(&htim4, &sMasterConfig) != HAL_OK)
  {
    Error_Handler();
  }
  sConfigIC.ICPolarity = TIM_INPUTCHANNELPOLARITY_RISING;
  sConfigIC.ICSelection = TIM_ICSELECTION_DIRECTTI;
  sConfigIC.ICPrescaler = TIM_ICPSC_DIV1;
  sConfigIC.ICFilter = 0;
  if (HAL_TIM_IC_ConfigChannel(&htim4, &sConfigIC, TIM_CHANNEL_1) != HAL_OK)
  {
    Error_Handler();
  }
  if (HAL_TIM_IC_ConfigChannel(&htim4, &sConfigIC, TIM_CHANNEL_2) != HAL_OK)
  {
    Error_Handler();
  }
  if (HAL_TIM_IC_ConfigChannel(&htim4, &sConfigIC, TIM_CHANNEL_3) != HAL_OK)
  {
    Error_Handler();
  }

}

static void MX_TIM5_Init(void)
{

  TIM_MasterConfigTypeDef sMasterConfig = {0};
  TIM_OC_InitTypeDef sConfigOC = {0};

  htim5.Instance = TIM5;
  htim5.Init.Prescaler = 0;
  htim5.Init.CounterMode = TIM_COUNTERMODE_UP;
  htim5.Init.Period = 4294967295;
  htim5.Init.ClockDivision = TIM_CLOCKDIVISION_DIV1;
  htim5.Init.AutoReloadPreload = TIM_AUTORELOAD_PRELOAD_DISABLE;
  if (HAL_TIM_PWM_Init(&htim5) != HAL_OK)
  {
    Error_Handler();
  }
  sMasterConfig.MasterOutputTrigger = TIM_TRGO_RESET;
  sMasterConfig.MasterSlaveMode = TIM_MASTERSLAVEMODE_DISABLE;
  if (HAL_TIMEx_MasterConfigSynchronization(&htim5, &sMasterConfig) != HAL_OK)
  {
    Error_Handler();
  }
  sConfigOC.OCMode = TIM_OCMODE_PWM1;
  sConfigOC.Pulse = 0;
  sConfigOC.OCPolarity = TIM_OCPOLARITY_HIGH;
  sConfigOC.OCFastMode = TIM_OCFAST_DISABLE;
  if (HAL_TIM_PWM_ConfigChannel(&htim5, &sConfigOC, TIM_CHANNEL_2) != HAL_OK)
  {
    Error_Handler();
  }
  if (HAL_TIM_PWM_ConfigChannel(&htim5, &sConfigOC, TIM_CHANNEL_3) != HAL_OK)
  {
    Error_Handler();
  }
  if (HAL_TIM_PWM_ConfigChannel(&htim5, &sConfigOC, TIM_CHANNEL_4) != HAL_OK)
  {
    Error_Handler();
  }
  HAL_TIM_MspPostInit(&htim5);

}

static void MX_TIM6_Init(void)
{

  TIM_MasterConfigTypeDef sMasterConfig = {0};

  htim6.Instance = TIM6;
  htim6.Init.Prescaler = 84 - 1;
  htim6.Init.CounterMode = TIM_COUNTERMODE_UP;
  htim6.Init.Period = 100 - 1;
  htim6.Init.AutoReloadPreload = TIM_AUTORELOAD_PRELOAD_DISABLE;
  if (HAL_TIM_Base_Init(&htim6) != HAL_OK)
  {
    Error_Handler();
  }
  sMasterConfig.MasterOutputTrigger = TIM_TRGO_RESET;
  sMasterConfig.MasterSlaveMode = TIM_MASTERSLAVEMODE_DISABLE;
  if (HAL_TIMEx_MasterConfigSynchronization(&htim6, &sMasterConfig) != HAL_OK)
  {
    Error_Handler();
  }

}

static void MX_TIM9_Init(void)
{

  TIM_IC_InitTypeDef sConfigIC = {0};

  htim9.Instance = TIM9;
  htim9.Init.Prescaler = 0;
  htim9.Init.CounterMode = TIM_COUNTERMODE_UP;
  htim9.Init.Period = 65535;
  htim9.Init.ClockDivision = TIM_CLOCKDIVISION_DIV1;
  htim9.Init.AutoReloadPreload = TIM_AUTORELOAD_PRELOAD_DISABLE;
  if (HAL_TIM_IC_Init(&htim9) != HAL_OK)
  {
    Error_Handler();
  }
  sConfigIC.ICPolarity = TIM_INPUTCHANNELPOLARITY_RISING;
  sConfigIC.ICSelection = TIM_ICSELECTION_DIRECTTI;
  sConfigIC.ICPrescaler = TIM_ICPSC_DIV1;
  sConfigIC.ICFilter = 0;
  if (HAL_TIM_IC_ConfigChannel(&htim9, &sConfigIC, TIM_CHANNEL_1) != HAL_OK)
  {
    Error_Handler();
  }
  sConfigIC.ICSelection = TIM_ICSELECTION_INDIRECTTI;
  if (HAL_TIM_IC_ConfigChannel(&htim9, &sConfigIC, TIM_CHANNEL_2) != HAL_OK)
  {
    Error_Handler();
  }

}

static void MX_TIM10_Init(void)
{

  TIM_OC_InitTypeDef sConfigOC = {0};

  htim10.Instance = TIM10;
  htim10.Init.Prescaler = 0;
  htim10.Init.CounterMode = TIM_COUNTERMODE_UP;
  htim10.Init.Period = 65535;
  htim10.Init.ClockDivision = TIM_CLOCKDIVISION_DIV1;
  htim10.Init.AutoReloadPreload = TIM_AUTORELOAD_PRELOAD_DISABLE;
  if (HAL_TIM_Base_Init(&htim10) != HAL_OK)
  {
    Error_Handler();
  }
  if (HAL_TIM_PWM_Init(&htim10) != HAL_OK)
  {
    Error_Handler();
  }
  sConfigOC.OCMode = TIM_OCMODE_PWM1;
  sConfigOC.Pulse = 0;
  sConfigOC.OCPolarity = TIM_OCPOLARITY_HIGH;
  sConfigOC.OCFastMode = TIM_OCFAST_DISABLE;
  if (HAL_TIM_PWM_ConfigChannel(&htim10, &sConfigOC, TIM_CHANNEL_1) != HAL_OK)
  {
    Error_Handler();
  }
  HAL_TIM_MspPostInit(&htim10);

}

static void MX_TIM11_Init(void)
{

  TIM_OC_InitTypeDef sConfigOC = {0};

  htim11.Instance = TIM11;
  htim11.Init.Prescaler = 0;
  htim11.Init.CounterMode = TIM_COUNTERMODE_UP;
  htim11.Init.Period = 65535;
  htim11.Init.ClockDivision = TIM_CLOCKDIVISION_DIV1;
  htim11.Init.AutoReloadPreload = TIM_AUTORELOAD_PRELOAD_DISABLE;
  if (HAL_TIM_Base_Init(&htim11) != HAL_OK)
  {
    Error_Handler();
  }
  if (HAL_TIM_PWM_Init(&htim11) != HAL_OK)
  {
    Error_Handler();
  }
  sConfigOC.OCMode = TIM_OCMODE_PWM1;
  sConfigOC.Pulse = 0;
  sConfigOC.OCPolarity = TIM_OCPOLARITY_HIGH;
  sConfigOC.OCFastMode = TIM_OCFAST_DISABLE;
  if (HAL_TIM_PWM_ConfigChannel(&htim11, &sConfigOC, TIM_CHANNEL_1) != HAL_OK)
  {
    Error_Handler();
  }
  HAL_TIM_MspPostInit(&htim11);

}

static void MX_TIM12_Init(void)
{

  TIM_IC_InitTypeDef sConfigIC = {0};

  htim12.Instance = TIM12;
  htim12.Init.Prescaler = 84 - 1;
  htim12.Init.CounterMode = TIM_COUNTERMODE_UP;
  htim12.Init.Period = 65535;
  htim12.Init.ClockDivision = TIM_CLOCKDIVISION_DIV1;
  htim12.Init.AutoReloadPreload = TIM_AUTORELOAD_PRELOAD_DISABLE;
  if (HAL_TIM_IC_Init(&htim12) != HAL_OK)
  {
    Error_Handler();
  }
  sConfigIC.ICPolarity = TIM_INPUTCHANNELPOLARITY_FALLING;
  sConfigIC.ICSelection = TIM_ICSELECTION_DIRECTTI;
  sConfigIC.ICPrescaler = TIM_ICPSC_DIV1;
  sConfigIC.ICFilter = 0;
  if (HAL_TIM_IC_ConfigChannel(&htim12, &sConfigIC, TIM_CHANNEL_1) != HAL_OK)
  {
    Error_Handler();
  }
  sConfigIC.ICPolarity = TIM_INPUTCHANNELPOLARITY_RISING;
  sConfigIC.ICSelection = TIM_ICSELECTION_INDIRECTTI;
  if (HAL_TIM_IC_ConfigChannel(&htim12, &sConfigIC, TIM_CHANNEL_2) != HAL_OK)
  {
    Error_Handler();
  }

}

static void MX_UART4_Init(void)
{

  huart4.Instance = UART4;
  huart4.Init.BaudRate = 115200;
  huart4.Init.WordLength = UART_WORDLENGTH_8B;
  huart4.Init.StopBits = UART_STOPBITS_1;
  huart4.Init.Parity = UART_PARITY_NONE;
  huart4.Init.Mode = UART_MODE_RX;
  huart4.Init.HwFlowCtl = UART_HWCONTROL_NONE;
  huart4.Init.OverSampling = UART_OVERSAMPLING_16;
  if (HAL_HalfDuplex_Init(&huart4) != HAL_OK)
  {
    Error_Handler();
  }

}

static void MX_USART1_UART_Init(void)
{

  huart1.Instance = USART1;
  huart1.Init.BaudRate = 115200;
  huart1.Init.WordLength = UART_WORDLENGTH_8B;
  huart1.Init.StopBits = UART_STOPBITS_1;
  huart1.Init.Parity = UART_PARITY_NONE;
  huart1.Init.Mode = UART_MODE_TX_RX;
  huart1.Init.HwFlowCtl = UART_HWCONTROL_NONE;
  huart1.Init.OverSampling = UART_OVERSAMPLING_16;
  if (HAL_UART_Init(&huart1) != HAL_OK)
  {
    Error_Handler();
  }

}

static void MX_USART2_UART_Init(void)
{

  huart2.Instance = USART2;
  huart2.Init.BaudRate = 115200;
  huart2.Init.WordLength = UART_WORDLENGTH_8B;
  huart2.Init.StopBits = UART_STOPBITS_1;
  huart2.Init.Parity = UART_PARITY_NONE;
  huart2.Init.Mode = UART_MODE_TX_RX;
  huart2.Init.HwFlowCtl = UART_HWCONTROL_NONE;
  huart2.Init.OverSampling = UART_OVERSAMPLING_16;
  if (HAL_UART_Init(&huart2) != HAL_OK)
  {
    Error_Handler();
  }

}

static void MX_USART3_UART_Init(void)
{

  huart3.Instance = USART3;
  huart3.Init.BaudRate = 115200;
  huart3.Init.WordLength = UART_WORDLENGTH_8B;
  huart3.Init.StopBits = UART_STOPBITS_1;
  huart3.Init.Parity = UART_PARITY_NONE;
  huart3.Init.Mode = UART_MODE_TX_RX;
  huart3.Init.HwFlowCtl = UART_HWCONTROL_NONE;
  huart3.Init.OverSampling = UART_OVERSAMPLING_16;
  if (HAL_UART_Init(&huart3) != HAL_OK)
  {
    Error_Handler();
  }

}

static void MX_GPIO_Init(void)
{
  GPIO_InitTypeDef GPIO_InitStruct = {0};

  /* GPIO Ports Clock Enable */
  __HAL_RCC_GPIOE_CLK_ENABLE();
  __HAL_RCC_GPIOH_CLK_ENABLE();
  __HAL_RCC_GPIOC_CLK_ENABLE();
  __HAL_RCC_GPIOA_CLK_ENABLE();
  __HAL_RCC_GPIOB_CLK_ENABLE();
  __HAL_RCC_GPIOD_CLK_ENABLE();

  /*Configure GPIO pin Output Level */
  HAL_GPIO_WritePin(GPIOE, US_TRIG_Pin|GPIO_PIN_3|GPIO_PIN_4|LORA_RST_Pin
                          |LED3_Pin|LORA_NSS_Pin|RTC_NC_Pin, GPIO_PIN_RESET);

  /*Configure GPIO pin Output Level */
  HAL_GPIO_WritePin(IMU_CS_GPIO_Port, IMU_CS_Pin, GPIO_PIN_SET);

  /*Configure GPIO pin Output Level */
  HAL_GPIO_WritePin(GPIOE, BMP_CS_Pin|LED1_Pin|LED2_Pin, GPIO_PIN_SET);

  /*Configure GPIO pin Output Level */
  HAL_GPIO_WritePin(GPIOB, LORA_DIO1_Pin|GPIO_PIN_15, GPIO_PIN_RESET);

  /*Configure GPIO pin Output Level */
  HAL_GPIO_WritePin(GPIOD, LORA_DIO2_Pin|LORA_DIO3_Pin, GPIO_PIN_RESET);

  /*Configure GPIO pins : US_TRIG_Pin PE3 PE4 LORA_RST_Pin
                           BMP_CS_Pin LED1_Pin LED2_Pin LED3_Pin
                           LORA_NSS_Pin RTC_NC_Pin */
  GPIO_InitStruct.Pin = US_TRIG_Pin|GPIO_PIN_3|GPIO_PIN_4|LORA_RST_Pin
                          |BMP_CS_Pin|LED1_Pin|LED2_Pin|LED3_Pin
                          |LORA_NSS_Pin|RTC_NC_Pin;
  GPIO_InitStruct.Mode = GPIO_MODE_OUTPUT_PP;
  GPIO_InitStruct.Pull = GPIO_NOPULL;
  GPIO_InitStruct.Speed = GPIO_SPEED_FREQ_LOW;
  HAL_GPIO_Init(GPIOE, &GPIO_InitStruct);

  /*Configure GPIO pin : IMU_CS_Pin */
  GPIO_InitStruct.Pin = IMU_CS_Pin;
  GPIO_InitStruct.Mode = GPIO_MODE_OUTPUT_PP;
  GPIO_InitStruct.Pull = GPIO_NOPULL;
  GPIO_InitStruct.Speed = GPIO_SPEED_FREQ_LOW;
  HAL_GPIO_Init(IMU_CS_GPIO_Port, &GPIO_InitStruct);

  /*Configure GPIO pins : LORA_DIO1_Pin PB15 */
  GPIO_InitStruct.Pin = LORA_DIO1_Pin|GPIO_PIN_15;
  GPIO_InitStruct.Mode = GPIO_MODE_OUTPUT_PP;
  GPIO_InitStruct.Pull = GPIO_NOPULL;
  GPIO_InitStruct.Speed = GPIO_SPEED_FREQ_LOW;
  HAL_GPIO_Init(GPIOB, &GPIO_InitStruct);

  /*Configure GPIO pins : LORA_DIO2_Pin LORA_DIO3_Pin */
  GPIO_InitStruct.Pin = LORA_DIO2_Pin|LORA_DIO3_Pin;
  GPIO_InitStruct.Mode = GPIO_MODE_OUTPUT_PP;
  GPIO_InitStruct.Pull = GPIO_NOPULL;
  GPIO_InitStruct.Speed = GPIO_SPEED_FREQ_LOW;
  HAL_GPIO_Init(GPIOD, &GPIO_InitStruct);

  /*Configure GPIO pin : GPS_INT_Pin */
  GPIO_InitStruct.Pin = GPS_INT_Pin;
  GPIO_InitStruct.Mode = GPIO_MODE_IT_RISING;
  GPIO_InitStruct.Pull = GPIO_NOPULL;
  HAL_GPIO_Init(GPS_INT_GPIO_Port, &GPIO_InitStruct);

}

/* USER CODE BEGIN 4 */
void HAL_TIM_IC_CaptureCallback(TIM_HandleTypeDef *htim){
	static uint8_t PPMCount;
	static uint32_t PWMCH2;

	if(htim->Instance == TIM12){
		if(htim->Channel == HAL_TIM_ACTIVE_CHANNEL_1){
			static uint32_t oldVal;
			static uint32_t nowVal;
			static uint32_t deltaFalling;

			nowVal = TIM12->CCR1;
			if(nowVal >= oldVal) deltaFalling = nowVal - oldVal;
			oldVal = nowVal;

			if(nowVal >= PWMCH2 && (nowVal - PWMCH2 >= 4000)){
				__HAL_TIM_SET_COUNTER(&htim12, 0);
				oldVal = 0;
				PPMCount = 0;
			} else {
				PPMOutput[PPMCount] = deltaFalling;
				PPMCount++;
			}

		}
		else if(htim->Channel == HAL_TIM_ACTIVE_CHANNEL_2){
			PWMCH2 = TIM12->CCR2;
		}

	}
}

void HAL_GPIO_EXTI_Callback(uint16_t GPIO_Pin){

}
/* USER CODE END 4 */

void Start_IMU_Task(void *argument)
{
  /* USER CODE BEGIN 5 */
	//static uint32_t curTick;
	  HAL_TIM_Base_Start_IT(&htim6);
	  HAL_TIM_Base_Start(&htim2);
  /* Infinite loop */
  for(;;)
  {
	  		  //strSize = sprintf((char*)strBuffer, "Orientation: %f %f %f\r\n", eulerAngles.angle.yaw - 29.85, eulerAngles.angle.pitch + 0.06, eulerAngles.angle.roll - 177.9);
	  		  //HAL_UART_Transmit_DMA(&SERIAL_DEBUG, strBuffer, strSize);

	  		  //printf("Orientation: %.4f %.4f %.4f\r\n", eulerAngles.angle.yaw, eulerAngles.angle.pitch, eulerAngles.angle.roll);
	    	//updateIMU = true;
	  		  printf("IMURateFreq: %f\r\n", IMURateFreq);

	   // if(updateIMU){
	  	 // updateIMU = false;

	    //}

	  /*if(osKernelGetTickCount() - curTick > 1000){
		  curTick = osKernelGetTickCount();

		  /*strSize = sprintf((char*)strBuffer, "accX: %f\taccY: %f\taccZ: %f\r\n", accX, accY, accZ);
		 HAL_UART_Transmit(&SERIAL_DEBUG, strBuffer, strSize, HAL_MAX_DELAY);

		  strSize = sprintf((char*)strBuffer, "gyrX: %f\tgyrY: %f\tgyrZ: %f\r\n", gyrX, gyrY, gyrZ);
		  HAL_UART_Transmit(&SERIAL_DEBUG, strBuffer, strSize, HAL_MAX_DELAY);

		 strSize = sprintf((char*)strBuffer, "magX: %f\tmagY: %f\tmagZ: %f\r\n\r\n", magX, magY, magZ);
		 HAL_UART_Transmit(&SERIAL_DEBUG, strBuffer, strSize, HAL_MAX_DELAY);

		 strSize = sprintf((char*)strBuffer, "Roll: %f\tPitch: %f\tYaw: %f\r\n", euler.roll, euler.pitch, euler.yaw);
		 HAL_UART_Transmit(&SERIAL_DEBUG, strBuffer, strSize, HAL_MAX_DELAY);

		 strSize = sprintf((char*)strBuffer, "Frame Rate Frequency: %f\r\n", IMURateFreq);
		 HAL_UART_Transmit(&SERIAL_DEBUG, strBuffer, strSize, HAL_MAX_DELAY);
	  }*/

	 /* if(updateIMU){
		  updateIMU = false;

		  accX = MPU9250_getAccelX_g(&mpu9250);
		  accY = MPU9250_getAccelY_g(&mpu9250);
		  accZ = MPU9250_getAccelZ_g(&mpu9250);

		  //gyrX = MPU9250_getGyroX_rads(&mpu9250);
		  //gyrY = MPU9250_getGyroY_rads(&mpu9250);
		  //gyrZ = MPU9250_getGyroZ_rads(&mpu9250);

		  gyrX = MPU9250_getGyroX_rads(&mpu9250);
		  gyrY = MPU9250_getGyroY_rads(&mpu9250);
		  gyrZ = MPU9250_getGyroZ_rads(&mpu9250);

		  magX = MPU9250_getMagX_uT(&mpu9250);
		  magY = MPU9250_getMagY_uT(&mpu9250);
		  magZ = MPU9250_getMagZ_uT(&mpu9250);

		  MadgwickQuaternionUpdate(accX, accY, accZ, gyrX, gyrY, gyrZ, magX, magY, magZ, (float)delta);
		  getQ(quaternion);

		  eulerAngles.angle.yaw   = atan2(2.0f * (*(quaternion+1) * *(quaternion+2) + *quaternion
						* *(quaternion+3)), *quaternion * *quaternion + *(quaternion+1)
						* *(quaternion+1) - *(quaternion+2) * *(quaternion+2) - *(quaternion+3)
						* *(quaternion+3));
		  eulerAngles.angle.pitch = -asin(2.0f * (*(quaternion+1) * *(quaternion+3) - *quaternion
						* *(quaternion+2)));
		  eulerAngles.angle.roll  = atan2(2.0f * (*quaternion * *(quaternion+1) + *(quaternion+2)
						* *(quaternion+3)), *quaternion * *quaternion - *(quaternion+1)
						* *(quaternion+1) - *(quaternion+2) * *(quaternion+2) + *(quaternion+3)
						* *(quaternion+3));
		  eulerAngles.angle.pitch *= RAD_TO_DEG;
		  eulerAngles.angle.yaw   *= RAD_TO_DEG;
		  //euler.yaw  -= 8.5;
		  eulerAngles.angle.yaw -= 0.81;
		  eulerAngles.angle.roll *= RAD_TO_DEG;
		  accel.axis.x = accX;
		  accel.axis.y = accY;
		  accel.axis.z = accZ;

		  gyro.axis.x = gyrX * RAD_TO_DEG;
		  gyro.axis.y = gyrY * RAD_TO_DEG;
		  gyro.axis.z = gyrZ * RAD_TO_DEG;

		  magnet.axis.x = magX;
		  magnet.axis.y = magY;
		  magnet.axis.z = magZ;

		  FusionAhrsUpdate(&fusionahrs, gyro, accel,  magnet, delta);
		  eulerAngles = FusionQuaternionToEulerAngles(FusionAhrsGetQuaternion(&fusionahrs));

		  //strSize = sprintf((char*)strBuffer, "Orientation: %f %f %f\r\n", eulerAngles.angle.yaw - 29.85, eulerAngles.angle.pitch + 0.06, eulerAngles.angle.roll - 177.9);
		  //HAL_UART_Transmit_DMA(&SERIAL_DEBUG, strBuffer, strSize);
	  }*/

	  /*if(updateRemote){
		  updateRemote = false;
		  strSize = sprintf((char*)strBuffer, "CH1: %d\tCH2: %d\tCH3: %d\tCH4: %d\tCH5: %d\tCH6: %d\r\n", PPMOutput[0], PPMOutput[1], PPMOutput[2], PPMOutput[3], PPMOutput[4], PPMOutput[5]);
		  //HAL_UART_Transmit_DMA(&SERIAL_DEBUG, strBuffer, strSize);
	  }*/
    osDelay(10);
  }
  /* USER CODE END 5 */
}

void Start_Remote_Task(void *argument)
{
  /* USER CODE BEGIN Start_Remote_Task */
	HAL_TIM_IC_Start_IT(&htim12, TIM_CHANNEL_1);
	HAL_TIM_IC_Start_IT(&htim12, TIM_CHANNEL_2);
  /* Infinite loop */
  for(;;)
  {
	  PPMRC.Roll = constrain(PPMOutput[0], 1000, 2000);
	  PPMRC.Pitch = constrain(PPMOutput[1], 1000, 2000);
	  PPMRC.Throttle = constrain(PPMOutput[2], 1000, 2000);
	  PPMRC.Yaw = constrain(PPMOutput[3], 1000, 2000);
	  PPMRC.SWB = constrain(PPMOutput[4], 1000, 2000);
	  PPMRC.SWC = constrain(PPMOutput[5], 1000, 2000);

	  //eulerInput.angle.pitch = (float)map((float)PPMRC.Pitch, 1000.0, 2000.0, -30.0, 30.0);
	  //eulerInput.angle.roll = (float)map((float)PPMRC.Roll, 1000.0, 2000.0, -30.0, 30.0);
	  //eulerInput.angle.yaw = (float)map((float)PPMRC.Yaw, 1000.0, 2000.0, -30.0, 30.0);

	  inputVel.xV = (float)map((float)PPMRC.Roll, 1000.0, 2000.0, -10.0, 10.0);
	  inputVel.yV = (float)map((float)PPMRC.Pitch, 1000.0, 2000.0, -10.0, 10.0);

	 //HAL_UART_Transmit_IT(&SERIAL_DEBUG, (uint8_t*)".\r\n", 4);

	//osEventFlagsWait(RemoteEventHandle, flag, osFlagsWaitAny, osWaitForever);
	//flag = osEventFlagsGet(RemoteEventHandle);
	//PPMOutput[flag] = prevCount;
	//__HAL_TIM_SET_COUNTER(&htim12, 0);
	//osEventFlagsClear(RemoteEventHandle, flag);

    osDelay(10);
  }
  /* USER CODE END Start_Remote_Task */
}

void Start_PrintSerial_Task(void *argument)
{
  /* USER CODE BEGIN Start_PrintSerial_Task */
  /* Infinite loop */
  for(;;)
  {
	//strSize = sprintf((char*)strBuffer, "CH1: %lu\tCH2: %lu\tCH3: %lu\tCH4: %lu\tCH5: %lu\tCH6: %lu\r\n", PPMOutput[0], PPMOutput[1], PPMOutput[2], PPMOutput[3], PPMOutput[4], PPMOutput[5]);
	//HAL_UART_Transmit_IT(&SERIAL_DEBUG, strBuffer, strSize);
	//strSize = sprintf((char*)strBuffer, "Velocity: %.2f %.2f\r\n", inputVel.xV, inputVel.yV);
	  //strSize = sprintf((char*)strBuffer, "Velocity\r\n");
	//HAL_UART_Transmit_IT(&SERIAL_DEBUG, strBuffer, strSize);

    osDelay(20);
  }
  /* USER CODE END Start_PrintSerial_Task */
}

void Start_BMP_Task(void *argument)
{
  /* USER CODE BEGIN Start_BMP_Task */
    struct bmp2_status status;
    struct bmp2_data comp_data;
    struct bmp2_dev dev;
    struct bmp2_config conf, test;
    int8_t rslt = BMP2_E_NULL_PTR;
    Kalman_t altitude_kalman;

	uint32_t meas_time;

	    /* Interface selection is to be updated as parameter
	     * For I2C :  BMP2_I2C_INTF
	     * For SPI :  BMP2_SPI_INTF
	     */
	  rslt = bmp2_interface_selection(&dev, BMP2_SPI_INTF);
	  bmp2_error_codes_print_result("bmp2_interface_selection", rslt);

	  rslt = bmp2_init(&dev);
	  bmp2_error_codes_print_result("bmp2_init", rslt);

	    /* Always read the current settings before writing, especially when all the configuration is not modified */
	  rslt = bmp2_get_config(&conf, &dev);
	  bmp2_error_codes_print_result("bmp2_get_config", rslt);

	    /* Configuring the over-sampling mode, filter coefficient and output data rate */
	    /* Overwrite the desired settings */
	  conf.filter = BMP2_FILTER_OFF;

	    /* Over-sampling mode is set as high resolution i.e., os_pres = 8x and os_temp = 1x */
	  conf.os_mode = BMP2_OS_MODE_CUSTOM;

	    /* Setting the output data rate */
	  conf.odr = BMP2_ODR_0_5_MS;

	  rslt = bmp2_set_config(&conf, &dev);
	  bmp2_error_codes_print_result("bmp2_set_config", rslt);

	    /* Set normal power mode */
	  rslt = bmp2_set_power_mode(BMP2_POWERMODE_NORMAL, &conf, &dev);
	  bmp2_error_codes_print_result("bmp2_set_power_mode", rslt);

	    /* Calculate measurement time in microseconds */
	  rslt = bmp2_compute_meas_time(&meas_time, &conf, &dev);
	  bmp2_error_codes_print_result("bmp2_compute_meas_time", rslt);

	    /* Read pressure and temperature data */
	  rslt = get_data(meas_time, &conf, &dev);
	  bmp2_error_codes_print_result("get_data", rslt);

	  rslt = bmp2_get_config(&test, &dev);
	  bmp2_error_codes_print_result("bmp2_get_config", rslt);

	  printf("os_temp: %d\r\n", test.os_temp);
	  printf("os_pres: %d\r\n", test.os_pres);
	  printf("filter: %d\r\n", test.filter);
	  printf("odr: %d\r\n", test.odr);
	  printf("powermode: %d\r\n", dev.power_mode);

	  HAL_SPI_DeInit(&hspi1);
	  hspi1.Init.BaudRatePrescaler = SPI_BAUDRATEPRESCALER_8;
	  if(HAL_SPI_Init(&hspi1) != HAL_OK) Error_Handler();

	   rslt = bmp2_get_status(&status, &dev);
	   bmp2_error_codes_print_result("bmp2_get_status", rslt);
	   uint32_t nData = 0;
	   static double tmpCalPres;

	  while(nData < 100){
		   rslt = bmp2_get_status(&status, &dev);
		   bmp2_error_codes_print_result("bmp2_get_status", rslt);

		   if(status.measuring == BMP2_MEAS_DONE){
				  rslt = bmp2_get_sensor_data(&comp_data, &dev);
				  bmp2_error_codes_print_result("bmp2_get_sensor_data", rslt);
				  comp_data.pressure /= 100.0;
				  tmpCalPres += comp_data.pressure;
				  nData++;
		   }
	  }

	  double calPres = tmpCalPres / 100.0;
	  kalman_init(&altitude_kalman, 0.12, 0.12, 44330.0 * (1.0 - pow(comp_data.pressure / calPres, 0.1903)));

  /* Infinite loop */
  for(;;)
  {
    rslt = bmp2_get_status(&status, &dev);
    bmp2_error_codes_print_result("bmp2_get_status", rslt);

    if(status.measuring == BMP2_MEAS_DONE){
    	rslt = bmp2_get_sensor_data(&comp_data, &dev);
    	bmp2_error_codes_print_result("bmp2_get_sensor_data", rslt);
    	if(rslt == BMP2_OK){
        	comp_data.pressure /= 100.0;
        	double altitude = 44330.0 * (1.0 - pow(comp_data.pressure / calPres, 0.1903));
        	double estimated_altitude = kalman_updateEstimate(&altitude_kalman, altitude);
        	//printf("%.4f\t%.4f\r\n", altitude, estimated_altitude);
    	}
    }
    osDelay(1);
  }
  /* USER CODE END Start_BMP_Task */
}

 /**
  * @brief  Period elapsed callback in non blocking mode
  * @note   This function is called  when TIM7 interrupt took place, inside
  * HAL_TIM_IRQHandler(). It makes a direct call to HAL_IncTick() to increment
  * a global variable "uwTick" used as application time base.
  * @param  htim : TIM handle
  * @retval None
  */
void HAL_TIM_PeriodElapsedCallback(TIM_HandleTypeDef *htim)
{
  if (htim->Instance == TIM7) {
    HAL_IncTick();
  }
  /* USER CODE BEGIN Callback 1 */
  if(htim->Instance == TIM6){
	  if(MPU9250_getDrdyStatus(&mpu9250)){
	  	    	MPU9250_readSensor(&mpu9250);
	  	    	cntPrev = cntNow;
	  	    	cntNow = __HAL_TIM_GET_COUNTER(&htim2);
	  	    	delta = ((float)cntNow - (float)cntPrev) / (1000000.0f);
	  	    	IMURateFreq = (1.0f / delta);

	  	  		  accX = MPU9250_getAccelX_g(&mpu9250);
	  	  		  accY = MPU9250_getAccelY_g(&mpu9250);
	  	  		  accZ = MPU9250_getAccelZ_g(&mpu9250);

	  	  		  //gyrX = MPU9250_getGyroX_rads(&mpu9250);
	  	  		  //gyrY = MPU9250_getGyroY_rads(&mpu9250);
	  	  		  //gyrZ = MPU9250_getGyroZ_rads(&mpu9250);

	  	  		  gyrX = MPU9250_getGyroX_rads(&mpu9250);
	  	  		  gyrY = MPU9250_getGyroY_rads(&mpu9250);
	  	  		  gyrZ = MPU9250_getGyroZ_rads(&mpu9250);

	  	  		  magX = MPU9250_getMagX_uT(&mpu9250);
	  	  		  magY = MPU9250_getMagY_uT(&mpu9250);
	  	  		  magZ = MPU9250_getMagZ_uT(&mpu9250);

	  	  		  MadgwickQuaternionUpdate(accX, accY, accZ, gyrX, gyrY, gyrZ, magX, magY, magZ, (float)delta);
	  	  		  getQ(quaternion);

	  	  		  eulerAngles.angle.yaw   = atan2(2.0f * (*(quaternion+1) * *(quaternion+2) + *quaternion
	  	  						* *(quaternion+3)), *quaternion * *quaternion + *(quaternion+1)
	  	  						* *(quaternion+1) - *(quaternion+2) * *(quaternion+2) - *(quaternion+3)
	  	  						* *(quaternion+3));
	  	  		  eulerAngles.angle.pitch = -asin(2.0f * (*(quaternion+1) * *(quaternion+3) - *quaternion
	  	  						* *(quaternion+2)));
	  	  		  eulerAngles.angle.roll  = atan2(2.0f * (*quaternion * *(quaternion+1) + *(quaternion+2)
	  	  						* *(quaternion+3)), *quaternion * *quaternion - *(quaternion+1)
	  	  						* *(quaternion+1) - *(quaternion+2) * *(quaternion+2) + *(quaternion+3)
	  	  						* *(quaternion+3));
	  	  		  eulerAngles.angle.pitch *= RAD_TO_DEG;
	  	  		  eulerAngles.angle.yaw   *= RAD_TO_DEG;
	  	  		  //euler.yaw  -= 8.5;
	  	  		  eulerAngles.angle.yaw -= 0.81;
	  	  		  eulerAngles.angle.roll *= RAD_TO_DEG;
	  	  		  accel.axis.x = accX;
	  	  		  accel.axis.y = accY;
	  	  		  accel.axis.z = accZ;

	  	  		  gyro.axis.x = gyrX * RAD_TO_DEG;
	  	  		  gyro.axis.y = gyrY * RAD_TO_DEG;
	  	  		  gyro.axis.z = gyrZ * RAD_TO_DEG;

	  	  		  magnet.axis.x = magX;
	  	  		  magnet.axis.y = magY;
	  	  		  magnet.axis.z = magZ;

	  	  		  FusionAhrsUpdate(&fusionahrs, gyro, accel,  magnet, delta);
	  	  		  eulerAngles = FusionQuaternionToEulerAngles(FusionAhrsGetQuaternion(&fusionahrs));
	  }
  }
  /* USER CODE END Callback 1 */
}

void Error_Handler(void)
{
  /* USER CODE BEGIN Error_Handler_Debug */
  /* User can add his own implementation to report the HAL error return state */
  __disable_irq();
  HAL_GPIO_WritePin(LED1_GPIO_Port, LED1_Pin, GPIO_PIN_RESET);
  HAL_GPIO_WritePin(LED1_GPIO_Port, LED3_Pin, GPIO_PIN_RESET);
  while (1)
  {
  }
  /* USER CODE END Error_Handler_Debug */
}

/************************ (C) COPYRIGHT STMicroelectronics *****END OF FILE****/

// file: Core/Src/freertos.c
/* USER CODE BEGIN Header */
/**
  ******************************************************************************
  * File Name          : freertos.c
  * Description        : Code for freertos applications
  ******************************************************************************
  * @attention
  *
  * <h2><center>&copy; Copyright (c) 2021 STMicroelectronics.
  * All rights reserved.</center></h2>
  *
  * This software component is licensed by ST under Ultimate Liberty license
  * SLA0044, the "License"; You may not use this file except in compliance with
  * the License. You may obtain a copy of the License at:
  *                             www.st.com/SLA0044
  *
  ******************************************************************************
  */
/* USER CODE END Header */

#include "FreeRTOS.h"
#include "task.h"
#include "main.h"
#include "cmsis_os.h"

/* Definitions for IMU_Task */
osThreadId_t IMU_TaskHandle;
const osThreadAttr_t IMU_Task_attributes = {
  .name = "IMU_Task",
  .stack_size = 128 * 4,
  .priority = (osPriority_t) osPriorityRealtime,
};

void Start_IMU_Task(void *argument);

void MX_FREERTOS_Init(void); /* (MISRA C 2004 rule 8.1) */

void MX_FREERTOS_Init(void) {

  /* Create the thread(s) */
  /* creation of IMU_Task */
  IMU_TaskHandle = osThreadNew(Start_IMU_Task, NULL, &IMU_Task_attributes);

}

void Start_IMU_Task(void *argument)
{
  for(;;)
  {
    osDelay(1);
  }
}

/************************ (C) COPYRIGHT STMicroelectronics *****END OF FILE****/
